# NM1500_v1 register map
File version: 1.0
NM1500_v1 SVD file
Registers are 32-bit, read-write, reset 0x0 unless marked. A register's access mark holds for its fields unless they carry their own. Offsets are from the block's base; lines under a group give offsets from that group; [hi:lo] are bit positions; {n}, {i} and the like mark numbered series; 'fields as' and 'values as' point back to an identical list; <NAME> marks a mode.

## Memory map
0x40004000 WDT size 0x8 — WDT Register Map
0x40004100 WWDT size 0x10 — WWDT Register Map
0x40010000 TMR01 blocks up to offset 0x3C — TIMER Register Map
0x40020000 I2C0 blocks up to offset 0x44 — I2C Register Map
0x40030000 SPI0 blocks up to offset 0x48 — SPI Register Map
0x40034000 SPI1 blocks up to offset 0x48 — SPI Register Map
0x40040000 BPWM blocks up to offset 0x80 — BPWM Register Map
0x40050000 UART0 size 0x3C — UART Register Map
0x400D0000 ACMP size 0x10 — ACMP Register Map
0x400E0000 ADC blocks up to offset 0xBC — ADC Register Map
0x400F0000 OPA size 0x8 — OPA Register Map
0x40110000 TMR23 blocks up to offset 0x3C — TIMER Register Map
0x40120000 I2C1 blocks up to offset 0x44 — I2C Register Map
0x40130000 SPI2 blocks up to offset 0x48 — SPI Register Map
0x40150000 UART1 size 0x3C — UART Register Map
0x40180000 CAN0 blocks up to offset 0x170 — CAN Register Map
0x40184000 CAN1 blocks up to offset 0x170 — CAN Register Map
0x40190000 EPWM0 blocks up to offset 0x44 — EPWM Register Map
0x40194000 EPWM1 blocks up to offset 0x44 — EPWM Register Map
0x401B0000 CAP0 size 0x20 — CAP Register Map
0x401B4000 CAP1 size 0x20 — CAP Register Map
0x401C0000 QEI0 blocks up to offset 0x30 — QEI Register Map
0x401C4000 QEI1 blocks up to offset 0x30 — QEI Register Map
0x401D0000 MDU0 blocks up to offset 0x13C — MDU Register Map
0x401D0400 MDU1 blocks up to offset 0x13C — MDU Register Map
0x401D0800 MDUG size 0x8 — MDU Register Map
0x50000000 GCR blocks up to offset 0x120 — GCR Register Map
0x50000200 CLK size 0x28 — CLK Register Map
0x50000300 INT size 0x88 — INT Register Map
0x50004000 GP0 blocks up to offset 0x2E8 — GPIO Register Map
{0x50004000+0x40*n} GP{n} size 0x24 (n=1..10) — GPIO Register Map
0x50004300 GPIOB size 0x160 — GPIO Register Map
0x5000C000 FMC blocks up to offset 0x44 — FMC Register Map
0x50014000 DIV size 0x18 — DIV Register Map
0xE000E010 SYST size 0xC — SYST Register Map
0xE000E100 NVIC blocks up to offset 0x320 — NVIC Register Map
0xE000ED00 SCB blocks up to offset 0x24 — SCB Register Map

## SYST — SYST Register Map
Base 0xE000E010
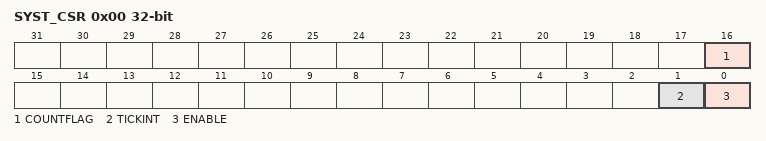
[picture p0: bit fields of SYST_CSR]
0x00 SYST_CSR — SysTick Control and Status Register
  [16] COUNTFLAG — SysTick flag. COUNTFLAG is set when the counter transitions to zero. COUNTFLAG is cleared by a read from this register or a write to the SYST_CVR.
  [1] TICKINT — Enables SysTick exception request.
    0=Counting down to zero does not assert the SysTick exception request; 1=Counting down to zero to asserts the SysTick exception request
  [0] ENABLE — Enables SysTick counter.
    0=SysTick counter Disabled; 1=SysTick counter Enabled
0x04 SYST_RVR reset not defined — SysTick Reload Value Register
  [23:0] RELOAD — Value to load into the SYST_CVR when the counter is enabled and when it reaches 0.
0x08 SYST_CVR reset not defined — SysTick Current Value Register
  [23:0] CURRENT — Reads return the current value of the SysTick counter. A write of any value clears the field to 0, and also clears the COUNTFLAG bit to 0.

## NVIC — NVIC Register Map
Base 0xE000E100
0x00 NVIC_ISER — IRQ0 ~ IRQ31 Set-Enable Control Register
  [31:0] SETENA — Interrupt Enable. The ISER enables interrupts, and shows the interrupts that are enabled. Each bit represents an IRQ number from IRQ0 ~ IRQ31 (Exception number from 16 ~ 47). Write:
    0=No effect. Interrupt Disabled; 1=Interrupt Enabled
0x80 NVIC_ICER — IRQ0 ~ IRQ31 Clear-Enable Control Register
  [31:0] CLRENA — Interrupt Clear Enable. The ICER disables interrupts, and shows the interrupts that are enabled. Each bit represents an IRQ number from IRQ0 ~ IRQ31 (Exception number from 16 ~ 47). Write:
    0=No effect. Interrupt Disabled; 1=Interrupt Disabled. Interrupt Enabled
0x100 NVIC_ISPR — IRQ0 ~ IRQ31 Set-Pending Control Register
  [31:0] SETPEND — Interrupt set-pending. The ISPR forces interrupts into the pending state, and shows the interrupts that are pending. Each bit represents an IRQ number from IRQ0 ~ IRQ31 (Exception number from 16 ~ 47). Write:
    0=no effect. interrupt is not pending; 1=changes interrupt state to pending. interrupt is pending
0x180 NVIC_ICPR — IRQ0 ~ IRQ31 Clear-Pending Control Register
  [31:0] CLRPEND — Interrupt clear-pending. The ICPR removes the pending state from interrupts, and shows the interrupts that are pending. Each bit represents an IRQ number from IRQ0 ~ IRQ31 (Exception number from 16 ~ 47). Write:
    0=no effect. interrupt is not pending; 1=removes pending state an interrupt. interrupt is pending
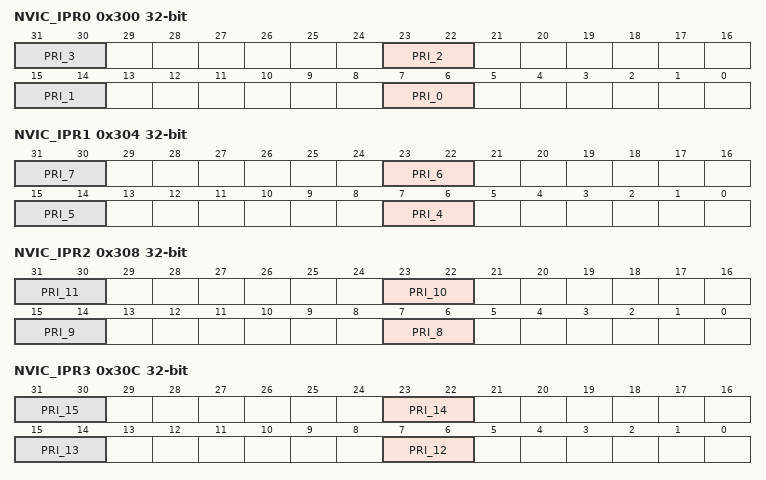
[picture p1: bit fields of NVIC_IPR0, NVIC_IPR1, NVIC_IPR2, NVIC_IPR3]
0x300 NVIC_IPR0 — IRQ0 ~ IRQ3 Interrupt Priority Control Register
  [8n+7:8n+6] PRI_{n} (n=0..3) — Priority of IRQ{n} '0' denotes the highest priority and '3' denotes lowest priority
0x304 NVIC_IPR1 — IRQ4 ~ IRQ7 Interrupt Priority Control Register
  [8n-25:8n-26] PRI_{n} (n=4..7) — Priority of IRQ{n} '0' denotes the highest priority and '3' denotes lowest priority
0x308 NVIC_IPR2 — IRQ8 ~ IRQ11 Interrupt Priority Control Register
  [8n-57:8n-58] PRI_{n} (n=8..11) — Priority of IRQ{n} '0' denotes the highest priority and '3' denotes lowest priority
0x30C NVIC_IPR3 — IRQ12 ~ IRQ15 Interrupt Priority Control Register
  [8n-89:8n-90] PRI_{n} (n=12..15) — Priority of IRQ{n} '0' denotes the highest priority and '3' denotes lowest priority
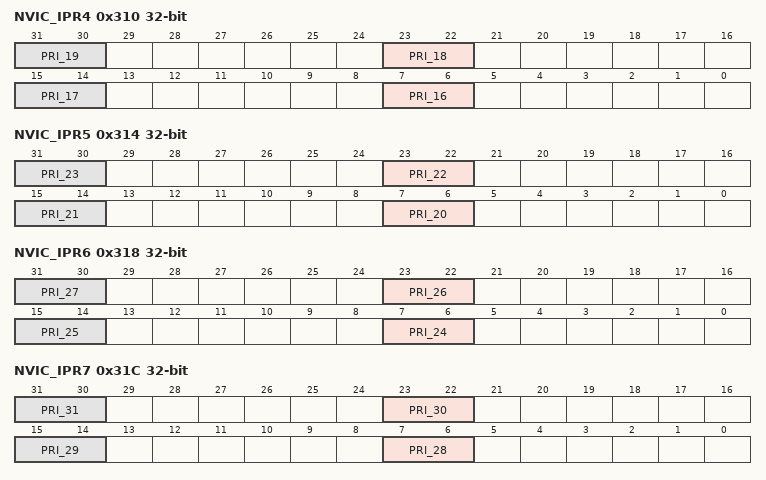
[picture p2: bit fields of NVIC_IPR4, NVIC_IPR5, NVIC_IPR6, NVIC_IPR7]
0x310 NVIC_IPR4 — IRQ16 ~ IRQ19 Interrupt Priority Control Register
  [8n-121:8n-122] PRI_{n} (n=16..19) — Priority of IRQ{n} '0' denotes the highest priority and '3' denotes lowest priority
0x314 NVIC_IPR5 — IRQ20 ~ IRQ23 Interrupt Priority Control Register
  [8n-153:8n-154] PRI_{n} (n=20..23) — Priority of IRQ{n} '0' denotes the highest priority and '3' denotes lowest priority
0x318 NVIC_IPR6 — IRQ24 ~ IRQ27 Interrupt Priority Control Register
  [8n-185:8n-186] PRI_{n} (n=24..27) — Priority of IRQ{n} '0' denotes the highest priority and '3' denotes lowest priority
0x31C NVIC_IPR7 — IRQ28 ~ IRQ31 Interrupt Priority Control Register
  [8n-217:8n-218] PRI_{n} (n=28..31) — Priority of IRQ{n} '0' denotes the highest priority and '3' denotes lowest priority
